# ESP32-P4-LP register map
Vendor: ESPRESSIF SYSTEMS (SHANGHAI) CO., LTD.; Series: ESP32 P-Series; File version: 3
CPU: RV32IMAC r0p0, little endian, no MPU, no FPU, 0 interrupt priority bits
Address unit: 32 bits
Registers are 32-bit, read-write, reset 0x0 unless marked. A register's access mark holds for its fields unless they carry their own. Offsets are from the block's base; [hi:lo] are bit positions.

## LP_I2S0 — Low-power I2S (Inter-IC Sound) Controller 0
Base 0x50125000
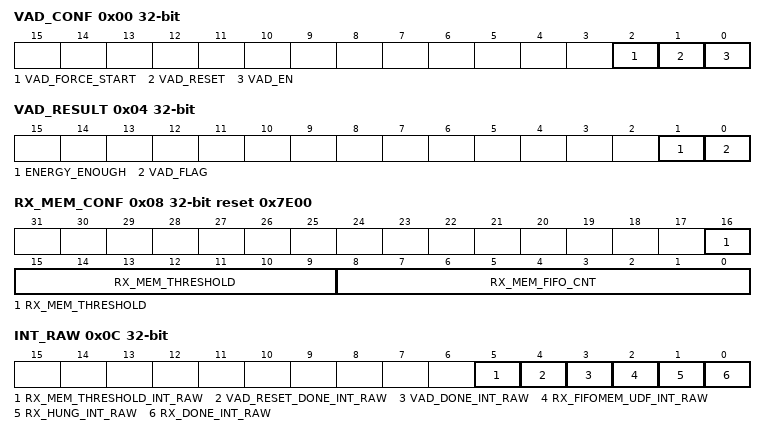
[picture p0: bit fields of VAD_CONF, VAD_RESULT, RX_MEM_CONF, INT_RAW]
0x00 VAD_CONF access per field — I2S VAD Configure register
  [2] VAD_FORCE_START wo
  [1] VAD_RESET wo
  [0] VAD_EN rw — VAD enable register
0x04 VAD_RESULT ro — I2S VAD Result register
  [1] ENERGY_ENOUGH — Reg energy enough observe signal
  [0] VAD_FLAG — Reg vad flag observe signal
0x08 RX_MEM_CONF access per field reset 0x7E00 — I2S VAD Observe register
  [16:9] RX_MEM_THRESHOLD rw — I2S rx mem will trigger an interrupt when the data in the mem is over(not including equal) reg_rx_mem_threshold
  [8:0] RX_MEM_FIFO_CNT ro — The number of data in the rx mem
0x0C INT_RAW ro — I2S interrupt raw register, valid in level.
  [5] RX_MEM_THRESHOLD_INT_RAW — The raw interrupt status bit for the rx_mem_threshold_int interrupt
  [4] VAD_RESET_DONE_INT_RAW — The raw interrupt status bit for the vad_reset_done_int interrupt
  [3] VAD_DONE_INT_RAW — The raw interrupt status bit for the vad_done_int interrupt
  [2] RX_FIFOMEM_UDF_INT_RAW — The raw interrupt status bit for the i2s_rx_fifomem_udf_int interrupt
  [1] RX_HUNG_INT_RAW — The raw interrupt status bit for the i2s_rx_hung_int interrupt
  [0] RX_DONE_INT_RAW — The raw interrupt status bit for the i2s_rx_done_int interrupt
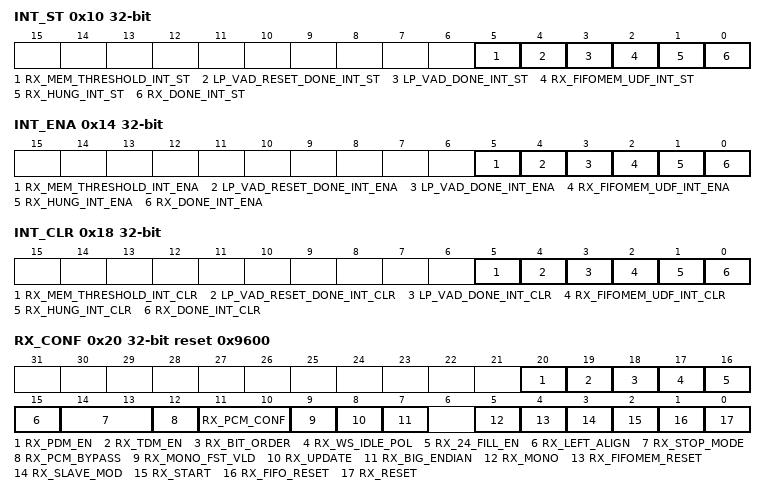
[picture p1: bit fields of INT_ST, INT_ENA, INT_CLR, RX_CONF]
0x10 INT_ST ro — I2S interrupt status register.
  [5] RX_MEM_THRESHOLD_INT_ST — The masked interrupt status bit for the rx_mem_threshold_int interrupt
  [4] LP_VAD_RESET_DONE_INT_ST — The masked interrupt status bit for the vad_reset_done_int interrupt
  [3] LP_VAD_DONE_INT_ST — The masked interrupt status bit for the vad_done_int interrupt
  [2] RX_FIFOMEM_UDF_INT_ST — The masked interrupt status bit for the i2s_rx_fifomem_udf_int interrupt
  [1] RX_HUNG_INT_ST — The masked interrupt status bit for the i2s_rx_hung_int interrupt
  [0] RX_DONE_INT_ST — The masked interrupt status bit for the i2s_rx_done_int interrupt
0x14 INT_ENA — I2S interrupt enable register.
  [5] RX_MEM_THRESHOLD_INT_ENA — The interrupt enable bit for the rx_mem_threshold_int interrupt
  [4] LP_VAD_RESET_DONE_INT_ENA — The interrupt enable bit for the vad_reset_done_int interrupt
  [3] LP_VAD_DONE_INT_ENA — The interrupt enable bit for the vad_done_int interrupt
  [2] RX_FIFOMEM_UDF_INT_ENA — The interrupt enable bit for the i2s_rx_fifomem_udf_int interrupt
  [1] RX_HUNG_INT_ENA — The interrupt enable bit for the i2s_rx_hung_int interrupt
  [0] RX_DONE_INT_ENA — The interrupt enable bit for the i2s_rx_done_int interrupt
0x18 INT_CLR wo — I2S interrupt clear register.
  [5] RX_MEM_THRESHOLD_INT_CLR — Set this bit to clear the rx_mem_threshold_int interrupt
  [4] LP_VAD_RESET_DONE_INT_CLR — Set this bit to clear the vad_reset_done_int interrupt
  [3] LP_VAD_DONE_INT_CLR — Set this bit to clear the vad_done_int interrupt
  [2] RX_FIFOMEM_UDF_INT_CLR — Set this bit to clear the i2s_rx_fifomem_udf_int interrupt
  [1] RX_HUNG_INT_CLR — Set this bit to clear the i2s_rx_hung_int interrupt
  [0] RX_DONE_INT_CLR — Set this bit to clear the i2s_rx_done_int interrupt
0x20 RX_CONF access per field reset 0x9600 — I2S RX configure register
  [20] RX_PDM_EN rw — 1: Enable I2S PDM Rx mode . 0: Disable.
  [19] RX_TDM_EN rw — 1: Enable I2S TDM Rx mode . 0: Disable.
  [18] RX_BIT_ORDER rw — I2S Rx bit endian. 1:small endian, the LSB is received first. 0:big endian, the MSB is received first.
  [17] RX_WS_IDLE_POL rw — 0: WS should be 0 when receiving left channel data, and WS is 1in right channel. 1: WS should be 1 when receiving left channel data, and WS is 0in right channel.
  [16] RX_24_FILL_EN rw — 1: store 24 channel bits to 32 bits. 0:store 24 channel bits to 24 bits.
  [15] RX_LEFT_ALIGN rw — 1: I2S RX left alignment mode. 0: I2S RX right alignment mode.
  [14:13] RX_STOP_MODE rw — 0 : I2S Rx only stop when reg_rx_start is cleared. 1: Stop when reg_rx_start is 0 or in_suc_eof is 1. 2: Stop I2S RX when reg_rx_start is 0 or RX FIFO is full.
  [12] RX_PCM_BYPASS rw — Set this bit to bypass Compress/Decompress module for received data.
  [11:10] RX_PCM_CONF rw — I2S RX compress/decompress configuration bit. & 0 (atol): A-Law decompress, 1 (ltoa) : A-Law compress, 2 (utol) : u-Law decompress, 3 (ltou) : u-Law compress. &
  [9] RX_MONO_FST_VLD rw — 1: The first channel data value is valid in I2S RX mono mode. 0: The second channel data value is valid in I2S RX mono mode.
  [8] RX_UPDATE rw — Set 1 to update I2S RX registers from APB clock domain to I2S RX clock domain. This bit will be cleared by hardware after update register done.
  [7] RX_BIG_ENDIAN rw — I2S Rx byte endian, 1: low addr value to high addr. 0: low addr with low addr value.
  [5] RX_MONO rw — Set this bit to enable receiver in mono mode
  [4] RX_FIFOMEM_RESET wo — Set this bit to reset Rx Syncfifomem
  [3] RX_SLAVE_MOD rw — Set this bit to enable slave receiver mode
  [2] RX_START rw — Set this bit to start receiving data
  [1] RX_FIFO_RESET wo — Set this bit to reset Rx AFIFO
  [0] RX_RESET wo — Set this bit to reset receiver
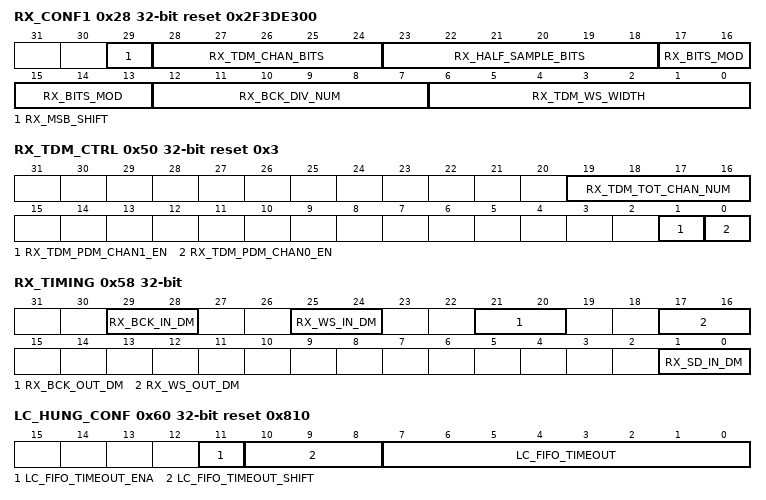
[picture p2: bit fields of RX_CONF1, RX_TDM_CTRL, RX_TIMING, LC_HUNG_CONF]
0x28 RX_CONF1 reset 0x2F3DE300 — I2S RX configure register 1
  [29] RX_MSB_SHIFT — Set this bit to enable receiver in Phillips standard mode
  [28:24] RX_TDM_CHAN_BITS — The Rx bit number for each channel minus 1in TDM mode.
  [23:18] RX_HALF_SAMPLE_BITS — I2S Rx half sample bits -1.
  [17:13] RX_BITS_MOD — Set the bits to configure the valid data bit length of I2S receiver channel. 7: all the valid channel data is in 8-bit-mode. 15: all the valid channel data is in 16-bit-mode. 23: all the valid channel data is in 24-bit-mode. 31:all the valid channel data is in 32-bit-mode.
  [12:7] RX_BCK_DIV_NUM — Bit clock configuration bits in receiver mode.
  [6:0] RX_TDM_WS_WIDTH — The width of rx_ws_out in TDM mode is (I2S_RX_TDM_WS_WIDTH[6:0] +1) * T_bck
0x50 RX_TDM_CTRL reset 0x3 — I2S TX TDM mode control register
  [19:16] RX_TDM_TOT_CHAN_NUM — The total channel number of I2S TX TDM mode.
  [1] RX_TDM_PDM_CHAN1_EN — 1: Enable the valid data input of I2S RX TDM or PDM channel 1. 0: Disable, just input 0 in this channel.
  [0] RX_TDM_PDM_CHAN0_EN — 1: Enable the valid data input of I2S RX TDM or PDM channel 0. 0: Disable, just input 0 in this channel.
0x58 RX_TIMING — I2S RX timing control register
  [29:28] RX_BCK_IN_DM — The delay mode of I2S Rx BCK input signal. 0: bypass. 1: delay by pos edge. 2: delay by neg edge. 3: not used.
  [25:24] RX_WS_IN_DM — The delay mode of I2S Rx WS input signal. 0: bypass. 1: delay by pos edge. 2: delay by neg edge. 3: not used.
  [21:20] RX_BCK_OUT_DM — The delay mode of I2S Rx BCK output signal. 0: bypass. 1: delay by pos edge. 2: delay by neg edge. 3: not used.
  [17:16] RX_WS_OUT_DM — The delay mode of I2S Rx WS output signal. 0: bypass. 1: delay by pos edge. 2: delay by neg edge. 3: not used.
  [1:0] RX_SD_IN_DM — The delay mode of I2S Rx SD input signal. 0: bypass. 1: delay by pos edge. 2: delay by neg edge. 3: not used.
0x60 LC_HUNG_CONF reset 0x810 — I2S HUNG configure register.
  [11] LC_FIFO_TIMEOUT_ENA — The enable bit for FIFO timeout
  [10:8] LC_FIFO_TIMEOUT_SHIFT — The bits are used to scale tick counter threshold. The tick counter is reset when counter value >= 88000/2^i2s_lc_fifo_timeout_shift
  [7:0] LC_FIFO_TIMEOUT — the i2s_tx_hung_int interrupt or the i2s_rx_hung_int interrupt will be triggered when fifo hung counter is equal to this value
0x64 RXEOF_NUM reset 0x40 — I2S RX data number control register.
  [11:0] RX_EOF_NUM — The receive data bit length is (I2S_RX_BITS_MOD[4:0] + 1) * (REG_RX_EOF_NUM[11:0] + 1) . It will trigger in_suc_eof interrupt in the configured DMA RX channel.
0x68 CONF_SIGLE_DATA — I2S signal data register
  [31:0] SINGLE_DATA — The configured constant channel data to be sent out.
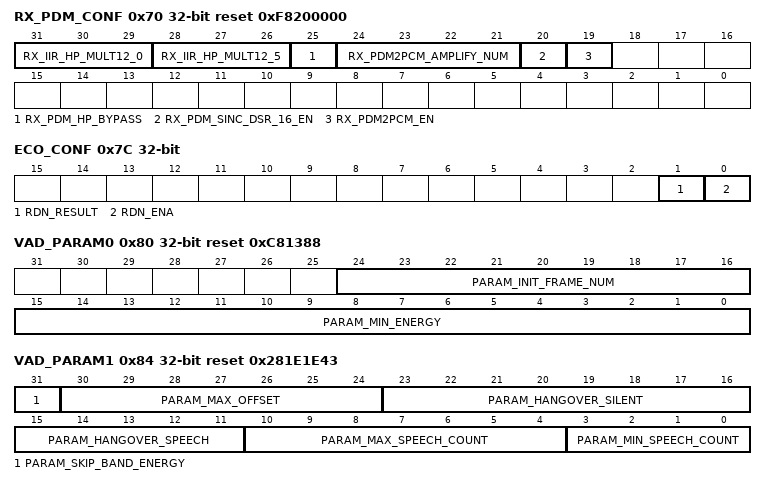
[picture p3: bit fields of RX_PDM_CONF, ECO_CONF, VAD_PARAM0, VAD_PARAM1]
0x70 RX_PDM_CONF reset 0xF8200000 — I2S RX configure register
  [31:29] RX_IIR_HP_MULT12_0 — The fourth parameter of PDM RX IIR_HP filter stage 1 is (504 + LP_I2S_RX_IIR_HP_MULT12_0[2:0])
  [28:26] RX_IIR_HP_MULT12_5 — The fourth parameter of PDM RX IIR_HP filter stage 2 is (504 + LP_I2S_RX_IIR_HP_MULT12_5[2:0])
  [25] RX_PDM_HP_BYPASS — I2S PDM RX bypass hp filter or not.
  [24:21] RX_PDM2PCM_AMPLIFY_NUM — Configure PDM RX amplify number.
  [20] RX_PDM_SINC_DSR_16_EN — Configure the down sampling rate of PDM RX filter group1 module. 1: The down sampling rate is 128. 0: down sampling rate is 64.
  [19] RX_PDM2PCM_EN — 1: Enable PDM2PCM RX mode. 0: DIsable.
0x74 ECO_LOW — I2S ECO register
  [31:0] RDN_ECO_LOW — logic low eco registers
0x78 ECO_HIGH reset 0xFFFFFFFF — I2S ECO register
  [31:0] RDN_ECO_HIGH — logic high eco registers
0x7C ECO_CONF access per field — I2S ECO register
  [1] RDN_RESULT ro
  [0] RDN_ENA rw — enable rdn counter bit
0x80 VAD_PARAM0 reset 0xC81388 — I2S VAD Parameter register
  [24:16] PARAM_INIT_FRAME_NUM — VAD parameter
  [15:0] PARAM_MIN_ENERGY — VAD parameter
0x84 VAD_PARAM1 reset 0x281E1E43 — I2S VAD Parameter register
  [31] PARAM_SKIP_BAND_ENERGY — Set 1 to skip band energy check.
  [30:24] PARAM_MAX_OFFSET — VAD parameter
  [23:16] PARAM_HANGOVER_SILENT — VAD parameter
  [15:11] PARAM_HANGOVER_SPEECH — VAD parameter
  [10:4] PARAM_MAX_SPEECH_COUNT — VAD parameter
  [3:0] PARAM_MIN_SPEECH_COUNT — VAD parameter
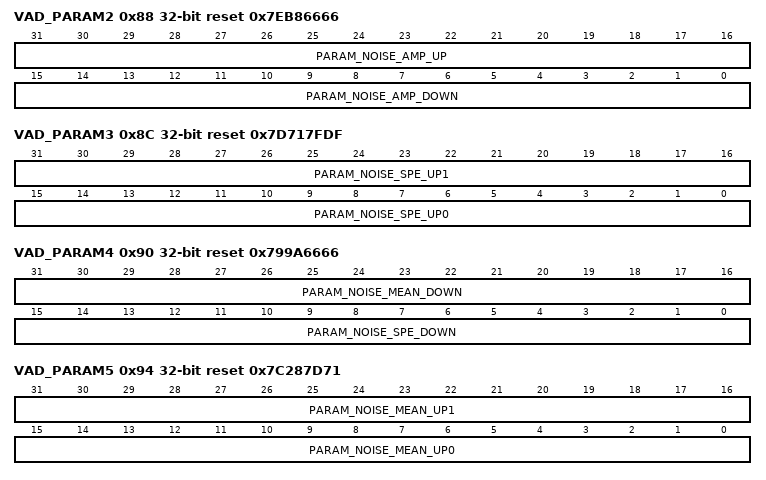
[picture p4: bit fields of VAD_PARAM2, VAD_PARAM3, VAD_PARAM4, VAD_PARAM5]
0x88 VAD_PARAM2 reset 0x7EB86666 — I2S VAD Parameter register
  [31:16] PARAM_NOISE_AMP_UP — VAD parameter
  [15:0] PARAM_NOISE_AMP_DOWN — VAD parameter
0x8C VAD_PARAM3 reset 0x7D717FDF — I2S VAD Parameter register
  [31:16] PARAM_NOISE_SPE_UP1 — VAD parameter
  [15:0] PARAM_NOISE_SPE_UP0 — VAD parameter
0x90 VAD_PARAM4 reset 0x799A6666 — I2S VAD Parameter register
  [31:16] PARAM_NOISE_MEAN_DOWN — VAD parameter
  [15:0] PARAM_NOISE_SPE_DOWN — VAD parameter
0x94 VAD_PARAM5 reset 0x7C287D71 — I2S VAD Parameter register
  [31:16] PARAM_NOISE_MEAN_UP1 — VAD parameter
  [15:0] PARAM_NOISE_MEAN_UP0 — VAD parameter
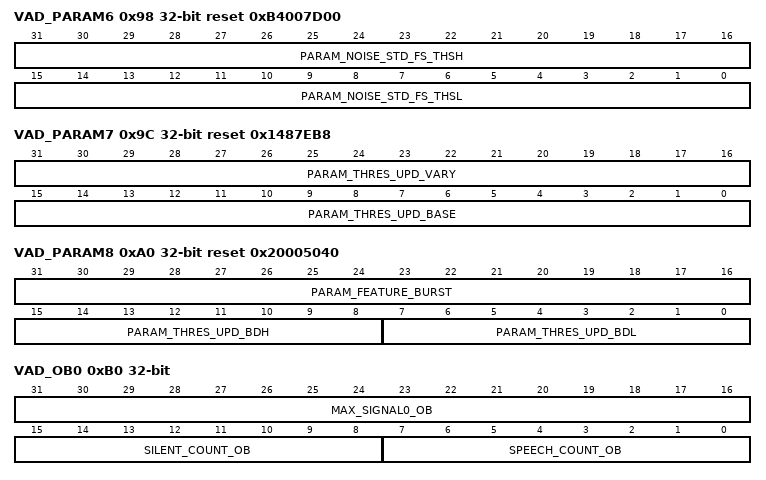
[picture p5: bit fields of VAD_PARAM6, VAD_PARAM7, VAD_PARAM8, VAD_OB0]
0x98 VAD_PARAM6 reset 0xB4007D00 — I2S VAD Parameter register
  [31:16] PARAM_NOISE_STD_FS_THSH — Feature_sum threshold to determine noise_std max value when vad_tag=0, equal to ((noise_std_max)>>11)^2*5
  [15:0] PARAM_NOISE_STD_FS_THSL — Feature_sum threshold to determine noise_std max value when vad_tag=1, equal to ((noise_std_max)>>11)^2*5
0x9C VAD_PARAM7 reset 0x1487EB8 — I2S VAD Parameter register
  [31:16] PARAM_THRES_UPD_VARY — VAD parameter
  [15:0] PARAM_THRES_UPD_BASE — VAD parameter
0xA0 VAD_PARAM8 reset 0x20005040 — I2S VAD Parameter register
  [31:16] PARAM_FEATURE_BURST — VAD parameter
  [15:8] PARAM_THRES_UPD_BDH — Noise_std boundary high when updating threshold.
  [7:0] PARAM_THRES_UPD_BDL — Noise_std boundary low when updating threshold.
0xB0 VAD_OB0 ro — I2S VAD Observe register
  [31:16] MAX_SIGNAL0_OB — Reg max signal0 observe
  [15:8] SILENT_COUNT_OB — Reg speech count observe
  [7:0] SPEECH_COUNT_OB — Reg silent count observe
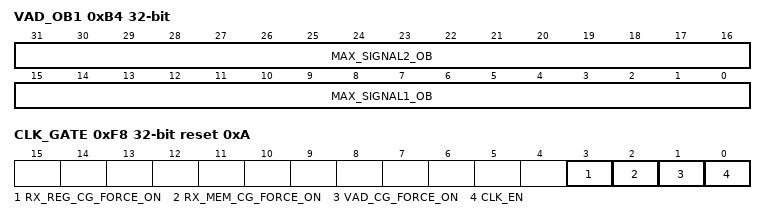
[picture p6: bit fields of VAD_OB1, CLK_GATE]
0xB4 VAD_OB1 ro — I2S VAD Observe register
  [31:16] MAX_SIGNAL2_OB — Reg max signal2 observe
  [15:0] MAX_SIGNAL1_OB — Reg max signal1 observe
0xB8 VAD_OB2 ro — I2S VAD Observe register
  [31:0] NOISE_AMP_OB — Reg noise_amp observe signal
0xBC VAD_OB3 ro — I2S VAD Observe register
  [31:0] NOISE_MEAN_OB — Reg noise_mean observe signal
0xC0 VAD_OB4 ro — I2S VAD Observe register
  [31:0] NOISE_STD_OB — Reg noise_std observe signal
0xC4 VAD_OB5 ro — I2S VAD Observe register
  [31:0] OFFSET_OB — Reg offset observe signal
0xC8 VAD_OB6 ro — I2S VAD Observe register
  [31:0] THRESHOLD_OB — Reg threshold observe signal
0xCC VAD_OB7 ro — I2S VAD Observe register
  [31:0] ENERGY_LOW_OB — Reg energy bit 31~0 observe signal
0xD0 VAD_OB8 ro — I2S VAD Observe register
  [31:0] ENERGY_HIGH_OB — Reg energy bit 63~32 observe signal
0xF8 CLK_GATE reset 0xA — Clock gate register
  [3] RX_REG_CG_FORCE_ON — I2S rx reg clock gate force on register
  [2] RX_MEM_CG_FORCE_ON — I2S rx mem clock gate force on register
  [1] VAD_CG_FORCE_ON — VAD clock gate force on register
  [0] CLK_EN — set this bit to enable clock gate
0xFC DATE reset 0x2305040 — Version control register
  [27:0] DATE — I2S version control register
